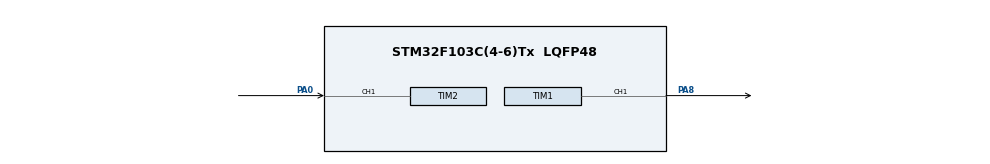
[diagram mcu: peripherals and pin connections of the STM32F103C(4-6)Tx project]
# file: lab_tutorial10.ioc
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Mcu.Family=STM32F1
Mcu.Name=STM32F103C(4-6)Tx
Mcu.Package=LQFP48
NVIC.PriorityGroup=NVIC_PRIORITYGROUP_4
NVIC.TIM2_IRQn=true\:0\:0\:false\:false\:true\:true\:true\:true
PA0-WKUP.Signal=S_TIM2_CH1_ETR
PA8.Signal=S_TIM1_CH1
ProjectManager.HeapSize=0x200
ProjectManager.StackSize=0x400
ProjectManager.TargetToolchain=MDK-ARM V5.32
RCC.APB1Freq_Value=8000000
RCC.APB2Freq_Value=8000000
SH.S_TIM1_CH1.0=TIM1_CH1,PWM Generation1 CH1
SH.S_TIM2_CH1_ETR.0=TIM2_CH1,Input_Capture1_from_TI1
TIM1.Channel-PWM\ Generation1\ CH1=TIM_CHANNEL_1
TIM1.Period=63999
TIM1.Prescaler=499
TIM1.Pulse-PWM\ Generation1\ CH1=47999
TIM2.Channel-Input_Capture1_from_TI1=TIM_CHANNEL_1
TIM2.Prescaler=7
VP_SYS_VS_ND.Mode=No_Debug
VP_TIM1_VS_ClockSourceINT.Mode=Internal
board=custom

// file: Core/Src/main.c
/* USER CODE BEGIN Header */
/**
  ******************************************************************************
  * @file           : main.c
  * @brief          : Main program body
  ******************************************************************************
  * @attention
  *
  * Copyright (c) 2025 STMicroelectronics.
  * All rights reserved.
  *
  * This software is licensed under terms that can be found in the LICENSE file
  * in the root directory of this software component.
  * If no LICENSE file comes with this software, it is provided AS-IS.
  *
  ******************************************************************************
  */
/* USER CODE END Header */
#include "main.h"

TIM_HandleTypeDef htim1;
TIM_HandleTypeDef htim2;

/* USER CODE BEGIN PV */
uint16_t icRisingEdgeValue = 0;
uint16_t icFallingEdgeValue = 0;
uint16_t icDifferenceValue = 0;
float pressingTime = 0;
uint8_t icFlag = 0;
uint16_t msWidth = 0;
float refClock = 1000000;    // (TIMCLOCK / PRESCALAR);

uint32_t IC_Val1 = 0;
uint32_t IC_Val2 = 0;
uint32_t Difference = 0;
int Is_First_Captured = 0;

/* Measure Frequency */
float frequency = 0;

/* USER CODE END PV */

void SystemClock_Config(void);
static void MX_GPIO_Init(void);
static void MX_TIM1_Init(void);
static void MX_TIM2_Init(void);

/* USER CODE BEGIN 0 */
//void HAL_TIM_IC_CaptureCallback(TIM_HandleTypeDef *htim)
//{
//    if (htim->Channel == HAL_TIM_ACTIVE_CHANNEL_1)
//    {
//        if (icFlag == 0)
//        {
//            icRisingEdgeValue = HAL_TIM_ReadCapturedValue(&htim2, TIM_CHANNEL_1);
//            icFlag = 1;
//        }
//        else
//        {
//            icFallingEdgeValue = HAL_TIM_ReadCapturedValue(&htim2, TIM_CHANNEL_1);
//            if (icFallingEdgeValue > icRisingEdgeValue)
//            {
//                icDifferenceValue = icFallingEdgeValue - icRisingEdgeValue;
//            }
//            else
//            {
//                icDifferenceValue = 0xFFFF + 1 + icFallingEdgeValue - icRisingEdgeValue;
//            }

//            msWidth = 1000 * ((float)icDifferenceValue) / refClock; // measure pulse width in ms;
//            icFlag = 0;
//        }
//    }
//}

void HAL_TIM_IC_CaptureCallback(TIM_HandleTypeDef *htim)
{
	if (htim->Channel == HAL_TIM_ACTIVE_CHANNEL_1)
	{
		if (Is_First_Captured==0) // if the first rising edge is not captured
		{
			IC_Val1 = HAL_TIM_ReadCapturedValue(htim, TIM_CHANNEL_1); // read the first value
			Is_First_Captured = 1;  // set the first captured as true
		}

		else   // If the first rising edge is captured, now we will capture the second edge
		{
			IC_Val2 = HAL_TIM_ReadCapturedValue(htim, TIM_CHANNEL_1);  // read second value

			if (IC_Val2 > IC_Val1)
			{
				Difference = IC_Val2-IC_Val1;
			}

			else if (IC_Val1 > IC_Val2)
			{
				Difference = (0xffffffff - IC_Val1) + IC_Val2;
			}

			float refClock = 1000000;

			frequency = refClock/Difference;

			__HAL_TIM_SET_COUNTER(htim, 0);  // reset the counter
			Is_First_Captured = 0; // set it back to false
		}
	}
}

/* USER CODE END 0 */

int main(void)
{

  /* MCU Configuration--------------------------------------------------------*/

  /* Reset of all peripherals, Initializes the Flash interface and the Systick. */
  HAL_Init();

  /* Configure the system clock */
  SystemClock_Config();

  /* Initialize all configured peripherals */
  MX_GPIO_Init();
  MX_TIM1_Init();
  MX_TIM2_Init();
  /* USER CODE BEGIN 2 */
	HAL_TIM_PWM_Start(&htim1, TIM_CHANNEL_1);
	HAL_TIM_IC_Start(&htim2, TIM_CHANNEL_1);
  /* USER CODE END 2 */

  /* Infinite loop */
  while (1)
  {

  }
}

void SystemClock_Config(void)
{
  RCC_OscInitTypeDef RCC_OscInitStruct = {0};
  RCC_ClkInitTypeDef RCC_ClkInitStruct = {0};

  /** Initializes the RCC Oscillators according to the specified parameters
  * in the RCC_OscInitTypeDef structure.
  */
  RCC_OscInitStruct.OscillatorType = RCC_OSCILLATORTYPE_HSI;
  RCC_OscInitStruct.HSIState = RCC_HSI_ON;
  RCC_OscInitStruct.HSICalibrationValue = RCC_HSICALIBRATION_DEFAULT;
  RCC_OscInitStruct.PLL.PLLState = RCC_PLL_NONE;
  if (HAL_RCC_OscConfig(&RCC_OscInitStruct) != HAL_OK)
  {
    Error_Handler();
  }

  /** Initializes the CPU, AHB and APB buses clocks
  */
  RCC_ClkInitStruct.ClockType = RCC_CLOCKTYPE_HCLK|RCC_CLOCKTYPE_SYSCLK
                              |RCC_CLOCKTYPE_PCLK1|RCC_CLOCKTYPE_PCLK2;
  RCC_ClkInitStruct.SYSCLKSource = RCC_SYSCLKSOURCE_HSI;
  RCC_ClkInitStruct.AHBCLKDivider = RCC_SYSCLK_DIV1;
  RCC_ClkInitStruct.APB1CLKDivider = RCC_HCLK_DIV1;
  RCC_ClkInitStruct.APB2CLKDivider = RCC_HCLK_DIV1;

  if (HAL_RCC_ClockConfig(&RCC_ClkInitStruct, FLASH_LATENCY_0) != HAL_OK)
  {
    Error_Handler();
  }
}

static void MX_TIM1_Init(void)
{

  TIM_ClockConfigTypeDef sClockSourceConfig = {0};
  TIM_MasterConfigTypeDef sMasterConfig = {0};
  TIM_OC_InitTypeDef sConfigOC = {0};
  TIM_BreakDeadTimeConfigTypeDef sBreakDeadTimeConfig = {0};

  htim1.Instance = TIM1;
  htim1.Init.Prescaler = 499;
  htim1.Init.CounterMode = TIM_COUNTERMODE_UP;
  htim1.Init.Period = 63999;
  htim1.Init.ClockDivision = TIM_CLOCKDIVISION_DIV1;
  htim1.Init.RepetitionCounter = 0;
  htim1.Init.AutoReloadPreload = TIM_AUTORELOAD_PRELOAD_DISABLE;
  if (HAL_TIM_Base_Init(&htim1) != HAL_OK)
  {
    Error_Handler();
  }
  sClockSourceConfig.ClockSource = TIM_CLOCKSOURCE_INTERNAL;
  if (HAL_TIM_ConfigClockSource(&htim1, &sClockSourceConfig) != HAL_OK)
  {
    Error_Handler();
  }
  if (HAL_TIM_PWM_Init(&htim1) != HAL_OK)
  {
    Error_Handler();
  }
  sMasterConfig.MasterOutputTrigger = TIM_TRGO_RESET;
  sMasterConfig.MasterSlaveMode = TIM_MASTERSLAVEMODE_DISABLE;
  if (HAL_TIMEx_MasterConfigSynchronization(&htim1, &sMasterConfig) != HAL_OK)
  {
    Error_Handler();
  }
  sConfigOC.OCMode = TIM_OCMODE_PWM1;
  sConfigOC.Pulse = 47999;
  sConfigOC.OCPolarity = TIM_OCPOLARITY_HIGH;
  sConfigOC.OCNPolarity = TIM_OCNPOLARITY_HIGH;
  sConfigOC.OCFastMode = TIM_OCFAST_DISABLE;
  sConfigOC.OCIdleState = TIM_OCIDLESTATE_RESET;
  sConfigOC.OCNIdleState = TIM_OCNIDLESTATE_RESET;
  if (HAL_TIM_PWM_ConfigChannel(&htim1, &sConfigOC, TIM_CHANNEL_1) != HAL_OK)
  {
    Error_Handler();
  }
  sBreakDeadTimeConfig.OffStateRunMode = TIM_OSSR_DISABLE;
  sBreakDeadTimeConfig.OffStateIDLEMode = TIM_OSSI_DISABLE;
  sBreakDeadTimeConfig.LockLevel = TIM_LOCKLEVEL_OFF;
  sBreakDeadTimeConfig.DeadTime = 0;
  sBreakDeadTimeConfig.BreakState = TIM_BREAK_DISABLE;
  sBreakDeadTimeConfig.BreakPolarity = TIM_BREAKPOLARITY_HIGH;
  sBreakDeadTimeConfig.AutomaticOutput = TIM_AUTOMATICOUTPUT_DISABLE;
  if (HAL_TIMEx_ConfigBreakDeadTime(&htim1, &sBreakDeadTimeConfig) != HAL_OK)
  {
    Error_Handler();
  }
  HAL_TIM_MspPostInit(&htim1);

}

static void MX_TIM2_Init(void)
{

  TIM_MasterConfigTypeDef sMasterConfig = {0};
  TIM_IC_InitTypeDef sConfigIC = {0};

  htim2.Instance = TIM2;
  htim2.Init.Prescaler = 7;
  htim2.Init.CounterMode = TIM_COUNTERMODE_UP;
  htim2.Init.Period = 65535;
  htim2.Init.ClockDivision = TIM_CLOCKDIVISION_DIV1;
  htim2.Init.AutoReloadPreload = TIM_AUTORELOAD_PRELOAD_DISABLE;
  if (HAL_TIM_IC_Init(&htim2) != HAL_OK)
  {
    Error_Handler();
  }
  sMasterConfig.MasterOutputTrigger = TIM_TRGO_RESET;
  sMasterConfig.MasterSlaveMode = TIM_MASTERSLAVEMODE_DISABLE;
  if (HAL_TIMEx_MasterConfigSynchronization(&htim2, &sMasterConfig) != HAL_OK)
  {
    Error_Handler();
  }
  sConfigIC.ICPolarity = TIM_INPUTCHANNELPOLARITY_RISING;
  sConfigIC.ICSelection = TIM_ICSELECTION_DIRECTTI;
  sConfigIC.ICPrescaler = TIM_ICPSC_DIV1;
  sConfigIC.ICFilter = 0;
  if (HAL_TIM_IC_ConfigChannel(&htim2, &sConfigIC, TIM_CHANNEL_1) != HAL_OK)
  {
    Error_Handler();
  }

}

static void MX_GPIO_Init(void)
{

  /* GPIO Ports Clock Enable */
  __HAL_RCC_GPIOA_CLK_ENABLE();

}

void Error_Handler(void)
{
  __disable_irq();
  while (1)
  {
  }
}
